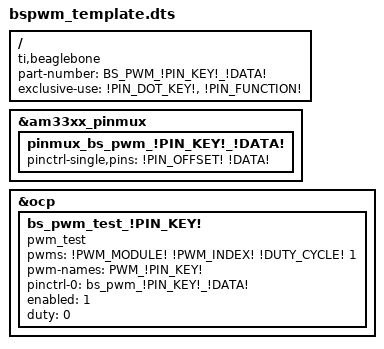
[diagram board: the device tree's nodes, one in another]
/*
 * Copyright (C) 2013 CircuitCo
 * Copyright (C) 2013 Texas Instruments
 *
 * This program is free software; you can redistribute it and/or modify
 * it under the terms of the GNU General Public License version 2 as
 * published by the Free Software Foundation.
 *
 * This is a template-generated file from BoneScript
 */
/dts-v1/;
/plugin/;

/ {
	compatible = "ti,beaglebone", "ti,beaglebone-black";

	/* identification */
	part-number = "BS_PWM_!PIN_KEY!_!DATA!";

	/* state the resources this cape uses */
	exclusive-use =
		/* the pin header uses */
		"!PIN_DOT_KEY!",
		/* the hardware IP uses */
		"!PIN_FUNCTION!";

	fragment@0 {
		target = <&am33xx_pinmux>;
		__overlay__ {
			bs_pwm_!PIN_KEY!_!DATA!: pinmux_bs_pwm_!PIN_KEY!_!DATA! {
				pinctrl-single,pins = <!PIN_OFFSET! !DATA!>;
			};
		};
	};

	fragment@1 {
		target = <&ocp>;
		__overlay__ {
			bs_pwm_test_!PIN_KEY! {
				compatible	= "pwm_test";
				pwms 		= <&!PWM_MODULE! !PWM_INDEX! !DUTY_CYCLE! 1>;
				pwm-names 	= "PWM_!PIN_KEY!";

				pinctrl-names	= "default";
				pinctrl-0	= <&bs_pwm_!PIN_KEY!_!DATA!>;

				enabled		= <1>;
				duty		= <0>;
				status 		= "okay";
			};
		};
	};
};
